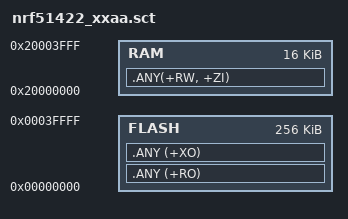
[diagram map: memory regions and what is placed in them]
LOAD 0x00000000 0x00040000
{
    FLASH 0x00000000 0x00040000
    {
    
        .ANY (+RO)
        .ANY (+XO)
    }

    RAM 0x20000000 0x00004000
    {
    .ANY(+RW, +ZI) ; RW data and ZI data
    }

}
